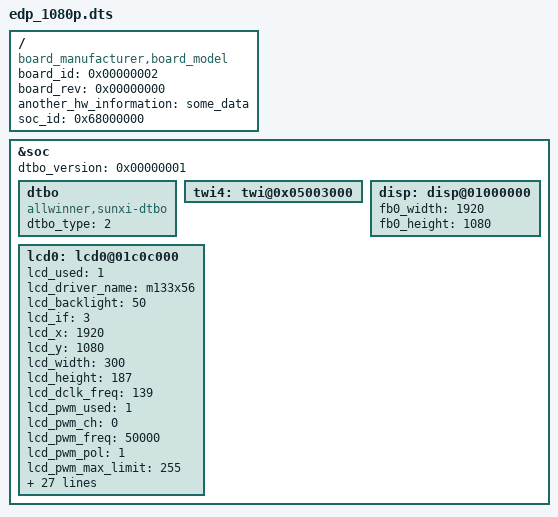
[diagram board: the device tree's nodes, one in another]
/dts-v1/;
/plugin/;
/ {
  /* As DTS design, these properties only for loader, won't overlay */
  compatible = "board_manufacturer,board_model";

  /* These properties are examples */
  board_id = <0x00000002>;
  board_rev = <0x00000000>;
  another_hw_information = "some_data";
  soc_id = <0x68000000>;

};

&soc {
	dtbo_version = <0x00000001>;
	dtbo{
		compatible = "allwinner,sunxi-dtbo";
		dtbo_type = <2>;
	};

	twi4: twi@0x05003000{
		status = "okay";
	};

	disp: disp@01000000 {
		fb0_width                = <1920>;
		fb0_height               = <1080>;
	};

	lcd0: lcd0@01c0c000 {
			lcd_used            = <1>;

			lcd_driver_name     = "m133x56";
			lcd_backlight       = <50>;
			lcd_if              = <3>;

			lcd_x               = <1920>;
			lcd_y               = <1080>;
			lcd_width           = <300>;
			lcd_height          = <187>;
			lcd_dclk_freq       = <139>;

			lcd_pwm_used        = <1>;
			lcd_pwm_ch          = <0>;
			lcd_pwm_freq        = <50000>;
			lcd_pwm_pol         = <1>;
			lcd_pwm_max_limit   = <255>;


			lcd_hbp             = <112>;
			lcd_ht              = <2380>;
			lcd_hspw            = <32>;
			lcd_vbp             = <29>;
			lcd_vt              = <1125>;
			lcd_vspw            = <5>;

			lcd_lvds_if         = <1>;
			lcd_lvds_colordepth = <0>;
			lcd_lvds_mode       = <0>;
			lcd_frm             = <0>;
			lcd_hv_clk_phase    = <0>;
			lcd_hv_sync_polarity= <0>;
			lcd_gamma_en        = <0>;
			lcd_bright_curve_en = <0>;
			lcd_cmap_en         = <0>;
			lcd_fsync_en        = <0>;
			lcd_fsync_act_time  = <1000>;
			lcd_fsync_dis_time  = <1000>;
			lcd_fsync_pol       = <0>;

			deu_mode            = <1>;
			lcdgamma4iep        = <22>;
			smart_color         = <90>;

			lcd_pin_power = "bldo1";

			lcd_power = "dc1sw";
			pinctrl-0 = <&lvds2link_pins_a>;
			pinctrl-1 = <&lvds2link_pins_b>;
			/* lcd_bl_en        = <&pio PE 19 1 0 3 1>; */
			/* PE = 4 */
			lcd_bl_en = <&pio 4 19 1 0 3 1>;

		};
};
